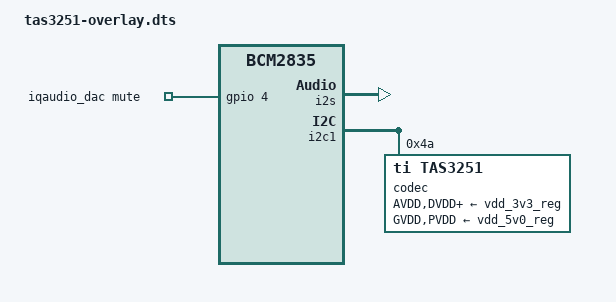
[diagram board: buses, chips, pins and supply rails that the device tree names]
// Definitions for IQaudIO DAC+
// dtc -I dts -O dtb -o /boot/overlays/tas3251.dtbo tas3251-overlay.dts
/dts-v1/;
/plugin/;

/ {
	compatible = "brcm,bcm2835";

	fragment@0 {
		target = <&i2s>;
		__overlay__ {
			status = "okay";
		};
	};

	fragment@1 {
		target = <&i2c1>;
		__overlay__ {
			#address-cells = <1>;
			#size-cells = <0>;
			status = "okay";

			codec: tas3251@4a {
				#sound-dai-cells = <0>;
				compatible = "ti,tas3251";
				reg = <0x4a>;
				AVDD-supply = <&vdd_3v3_reg>;
				DVDD-supply = <&vdd_3v3_reg>;
				CPVDD-supply = <&vdd_3v3_reg>;
				GVDD-supply = <&vdd_5v0_reg>;
				PVDD-supply = <&vdd_5v0_reg>;

				status = "okay";
			};
		};
	};

	fragment@2 {
		target = <&sound>;
		iqaudio_dac: __overlay__ {
			compatible = "iqaudio,iqaudio-dac";
			i2s-controller = <&i2s>;
			card_name = "AmpliMuseAMP2";
			dai_name = "AmpliMuse Amp2";
			dai_stream_name = "AmpliMuse Amp2 HiFi";
			mute-gpios = <&gpio 4 0>;
			status = "okay";
		};
	};

	__overrides__ {
		24db_digital_gain = <&iqaudio_dac>,"iqaudio,24db_digital_gain?";
		auto_mute_amp = <&iqaudio_dac>,"iqaudio-dac,auto-mute-amp?";
		unmute_amp = <&iqaudio_dac>,"iqaudio-dac,unmute-amp?";
		i2creg = <&codec>,"reg:<>";
	};
};
